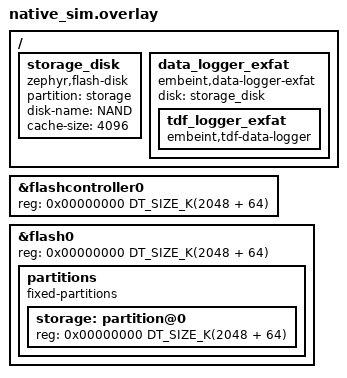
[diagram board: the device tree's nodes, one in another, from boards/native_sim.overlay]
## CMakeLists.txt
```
# SPDX-License-Identifier: Apache-2.0

cmake_minimum_required(VERSION 3.20.0)
find_package(Zephyr REQUIRED HINTS $ENV{ZEPHYR_BASE})
project(tdf_exfat)

target_sources(app PRIVATE
  src/main.c
)
```

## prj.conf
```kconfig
CONFIG_ZTEST=y
CONFIG_DATA_LOGGER=y
CONFIG_DATA_LOGGER_EXFAT_FILE_SIZE=8192
CONFIG_INFUSE_EPOCH_TIME=y
CONFIG_MAIN_STACK_SIZE=4096
CONFIG_ZTEST_STACK_SIZE=4096
CONFIG_NET_BUF=y
CONFIG_NET_BUF_POOL_USAGE=y
CONFIG_TDF_DATA_LOGGER=y
CONFIG_TDF=y

# Disk Access
CONFIG_FLASHDISK_LOG_LEVEL_WRN=y

# exFAT filesystem
CONFIG_FILE_SYSTEM_LIB_LINK=y
```

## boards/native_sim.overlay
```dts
/*
 * Copyright (c) 2023 Antmicro
 *
 * SPDX-License-Identifier: Apache-2.0
 */
 #include <mem.h>

&flashcontroller0 {
	reg = <0x00000000 DT_SIZE_K(2048 + 64)>;
};

&flash0 {
	reg = <0x00000000 DT_SIZE_K(2048 + 64)>;
	partitions {
		compatible = "fixed-partitions";
		#address-cells = <1>;
		#size-cells = <1>;

		storage: partition@0 {
			reg = <0x00000000 DT_SIZE_K(2048 + 64)>;
		};
	};
};

/ {
	storage_disk: storage_disk {
		compatible = "zephyr,flash-disk";
		partition = <&storage>;
		disk-name = "NAND";
		cache-size = <4096>;
	};

	data_logger_exfat: data_logger_exfat {
		compatible = "embeint,data-logger-exfat", "embeint,data-logger";
		disk = <&storage_disk>;

		tdf_logger_exfat: tdf_logger_exfat {
			compatible = "embeint,tdf-data-logger";
		};
	};
};
```

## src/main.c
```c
/**
 * @file
 * @copyright 2024 Embeint Holdings Pty Ltd
 * @author Jordan Yates <jordan@embeint.com>
 *
 * SPDX-License-Identifier: FSL-1.1-ALv2
 */

#include <string.h>

#include <zephyr/ztest.h>
#include <zephyr/kernel.h>
#include <zephyr/storage/disk_access.h>

#include <infuse/data_logger/logger.h>
#include <infuse/data_logger/high_level/tdf.h>

#include <ff.h>

enum {
	TDF_RANDOM = 37,
};

ZTEST(tdf_data_logger_exfat, test_block_padding)
{
	const struct device *tdf_logger = DEVICE_DT_GET(DT_NODELABEL(tdf_logger_exfat));
	const struct device *data_logger = DEVICE_DT_GET(DT_NODELABEL(data_logger_exfat));
	struct data_logger_state state;
	uint8_t tdf_data[32];
	int rc;

	/* 20 bytes per log (3 overhead, 17 data) = 160 bytes */
	for (int i = 0; i < 8; i++) {
		rc = tdf_data_logger_log_dev(tdf_logger, TDF_RANDOM, 17, 0, tdf_data);
		zassert_equal(0, rc);
	}
	data_logger_get_state(data_logger, &state);
	zassert_equal(0, state.current_block);

	/* Flush logger (Data should be padded and not assert) */
	rc = tdf_data_logger_flush_dev(tdf_logger);
	zassert_true(rc > 0);
	data_logger_get_state(data_logger, &state);
	zassert_equal(1, state.current_block);
}

ZTEST_SUITE(tdf_data_logger_exfat, NULL, NULL, NULL, NULL, NULL);
```
